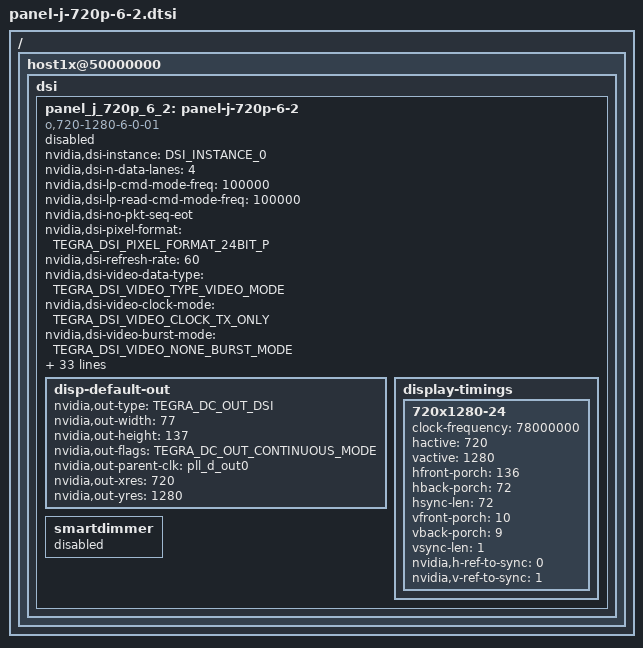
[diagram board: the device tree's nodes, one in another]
/*
 * JDI LPM062M326A / LAM062M109A
 *
 * Copyright (c) 2015-2017, NVIDIA CORPORATION.  All rights reserved.
 * Copyright (c) 2020, CTCaer <ctcaer@gmail.com>
 *
 * This program is free software; you can redistribute it and/or modify
 * it under the terms of the GNU General Public License as published by
 * the Free Software Foundation; either version 2 of the License, or
 * (at your option) any later version.
 *
 * This program is distributed in the hope that it will be useful, but WITHOUT
 * ANY WARRANTY; without even the implied warranty of MERCHANTABILITY or
 * FITNESS FOR A PARTICULAR PURPOSE.  See the GNU General Public License for
 * more details.
 *
 * You should have received a copy of the GNU General Public License along
 * with this program; if not, write to the Free Software Foundation, Inc.,
 * 51 Franklin Street, Fifth Floor, Boston, MA  02110-1301, USA.
 */
#include <dt-bindings/display/tegra-dc.h>
#include <dt-bindings/display/tegra-panel.h>

/ {
	host1x@50000000 {
		dsi {
			panel_j_720p_6_2: panel-j-720p-6-2 {
				status = "disabled";
				compatible = "o,720-1280-6-0-01"; /* Compatible id must not change! */
				/*
				nvidia,edid = [
						00 FF FF FF FF FF FF 00 28 89 10 0F 00 00 00 00
						01 1A 01 03 80 08 0E 00 1A 00 00 00 00 00 00 00
						00 00 00 00 00 00 01 01 01 01 01 01 01 01 01 01
						01 01 01 01 01 01 78 1E D0 18 21 00 14 50 88 48
						A1 00 4D 89 00 00 00 00 00 00 00 10 00 00 00 00
						00 00 00 00 00 00 00 00 00 00 00 00 00 10 00 00
						00 00 00 00 00 00 00 00 00 00 00 00 00 00 00 10
						00 00 00 00 00 00 00 00 00 00 00 00 00 00 00 DD];
				*/
				nvidia,dsi-instance = <DSI_INSTANCE_0>;
				nvidia,dsi-n-data-lanes = <4>;
				nvidia,dsi-lp-cmd-mode-freq = <100000>;
				nvidia,dsi-lp-read-cmd-mode-freq = <100000>;
				nvidia,dsi-no-pkt-seq-eot;
				nvidia,dsi-pixel-format = <TEGRA_DSI_PIXEL_FORMAT_24BIT_P>;
				nvidia,dsi-refresh-rate = <60>;
				nvidia,dsi-video-data-type = <TEGRA_DSI_VIDEO_TYPE_VIDEO_MODE>;
				nvidia,dsi-video-clock-mode = <TEGRA_DSI_VIDEO_CLOCK_TX_ONLY>;
				nvidia,dsi-video-burst-mode = <TEGRA_DSI_VIDEO_NONE_BURST_MODE>;
				nvidia,dsi-virtual-channel = <TEGRA_DSI_VIRTUAL_CHANNEL_0>;
				nvidia,dsi-panel-reset = <TEGRA_DSI_ENABLE>;
				nvidia,dsi-power-saving-suspend = <TEGRA_DSI_ENABLE>;
				nvidia,dsi-ulpm-not-support = <TEGRA_DSI_ENABLE>;
				nvidia,dsi-phy-tlpx = <100>;
				nvidia,dsi-init-cmd =
					<TEGRA_DSI_PACKET_CMD DSI_DCS_LONG_WRITE 0x04 0x00 0x0
						0xB9 0xFF 0x83 0x94
						0x0 0x0>,
					<TEGRA_DSI_PACKET_CMD DSI_DCS_WRITE_1_PARAM 0xBD 0x00 0x0>,
					<TEGRA_DSI_PACKET_CMD DSI_DCS_LONG_WRITE 0x19 0x00 0x0
						0xD8 0xAA 0xAA 0xAA 0xEB 0xAA 0xAA 0xAA
						0xAA 0xAA 0xEB 0xAA 0xAA 0xAA 0xAA 0xAA
						0xEB 0xAA 0xAA 0xAA 0xAA 0xAA 0xEB 0xAA
						0xAA
						0x0 0x0>,
					<TEGRA_DSI_PACKET_CMD DSI_DCS_WRITE_1_PARAM 0xBD 0x01 0x0>,
					<TEGRA_DSI_PACKET_CMD DSI_DCS_LONG_WRITE 0x27 0x00 0x0
						0xD8 0xFF 0xFF 0xFF 0xFF 0xFF 0xFF 0xFF
						0xFF 0xFF 0xFF 0xFF 0xFF 0xFF 0xFF 0xFF
						0xFF 0xFF 0xFF 0xFF 0xFF 0xFF 0xFF 0xFF
						0xFF 0xFF 0xFF 0xFF 0xFF 0xFF 0xFF 0xFF
						0xFF 0xFF 0xFF 0xFF 0xFF 0xFF 0xFF
						0x0 0x0>,
					<TEGRA_DSI_PACKET_CMD DSI_DCS_WRITE_1_PARAM 0xBD 0x02 0x0>,
					<TEGRA_DSI_PACKET_CMD DSI_DCS_LONG_WRITE 0x0F 0x00 0x0
						0xD8 0xFF 0xFF 0xFF 0xFF 0xFF 0xFF 0xFF
						0xFF 0xFF 0xFF 0xFF 0xFF 0xFF 0xFF
						0x0 0x0>,
					<TEGRA_DSI_PACKET_CMD DSI_DCS_WRITE_1_PARAM 0xBD 0x00 0x00>,
					<TEGRA_DSI_PACKET_CMD DSI_DCS_WRITE_1_PARAM 0xD9 0x06 0x0>,
					<TEGRA_DSI_PACKET_CMD DSI_DCS_LONG_WRITE 0x04 0x00 0x00
						0xB9 0x00 0x00 0x00
						0x0 0x0>,
					<TEGRA_DSI_PACKET_CMD DSI_DCS_WRITE_0_PARAM DSI_DCS_EXIT_SLEEP_MODE 0x00 0x0>,
					<TEGRA_DSI_DELAY_MS 180>, //180ms
					/* TODO, Do we need to find a way to set set_display_on after "operate DSI_A in video mode"? */
					<TEGRA_DSI_PACKET_CMD DSI_DCS_WRITE_0_PARAM DSI_DCS_SET_DISPLAY_ON 0x00 0x0>,
					<TEGRA_DSI_DELAY_MS 20>; //20ms
				nvidia,dsi-n-init-cmd = <14>;
				nvidia,dsi-suspend-cmd =
					<TEGRA_DSI_PACKET_CMD DSI_DCS_WRITE_0_PARAM DSI_DCS_SET_DISPLAY_OFF 0x00 0x0>,
					<TEGRA_DSI_DELAY_MS 50>, //40ms + 10ms
					<TEGRA_DSI_PACKET_CMD DSI_DCS_LONG_WRITE 0x04 0x00 0x0
						0xB9 0xFF 0x83 0x94
						0x0 0x0>,
					<TEGRA_DSI_PACKET_CMD DSI_DCS_LONG_WRITE 0x21 0x00 0x0
						0xD5 0x19 0x19 0x19 0x19 0x19 0x19 0x19
						0x19 0x19 0x19 0x19 0x19 0x19 0x19 0x19
						0x19 0x19 0x19 0x19 0x19 0x19 0x19 0x19
						0x19 0x19 0x19 0x19 0x19 0x19 0x19 0x19
						0x19
						0x0 0x0>,
					<TEGRA_DSI_PACKET_CMD DSI_DCS_LONG_WRITE 0x0B 0x00 0x0
						0xB1 0x41 0x0F 0x4F 0x33 0xA4 0x79 0xF1
						0x81 0x2D 0x00
						0x0 0x0>,
					<TEGRA_DSI_PACKET_CMD DSI_DCS_LONG_WRITE 0x04 0x00 0x0
						0xB9 0x00 0x00 0x00
						0x0 0x0>,
					<TEGRA_DSI_PACKET_CMD DSI_DCS_WRITE_0_PARAM DSI_DCS_ENTER_SLEEP_MODE 0x00 0x0>,
					<TEGRA_DSI_DELAY_MS 50>; //50ms
				nvidia,dsi-n-suspend-cmd = <8>;
				disp-default-out {
					nvidia,out-type = <TEGRA_DC_OUT_DSI>;
					nvidia,out-width = <77>;
					nvidia,out-height = <137>;
					nvidia,out-flags = <TEGRA_DC_OUT_CONTINUOUS_MODE>;
					nvidia,out-parent-clk = "pll_d_out0";
					nvidia,out-xres = <720>;
					nvidia,out-yres = <1280>;
				};
				display-timings {
					720x1280-24 {
						clock-frequency = <78000000>; /* (720+136+144) x (1280+10+10) x 60 */
						hactive = <720>;
						vactive = <1280>;

						hfront-porch = <136>;
						hback-porch = <72>;
						hsync-len = <72>;

						vfront-porch = <10>;
						vback-porch = <9>;
						vsync-len = <1>;

						/* For DSI these are automatically calculated */
						nvidia,h-ref-to-sync = <0>;
						nvidia,v-ref-to-sync = <1>;
					};
				};
				smartdimmer {
					status = "disabled";
				};
			};
		};
	};
};
